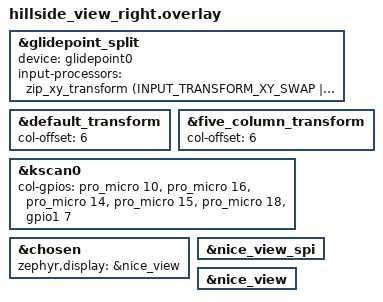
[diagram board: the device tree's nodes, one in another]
/*
 * Copyright (c) 2022 The ZMK Contributors
 *
 * SPDX-License-Identifier: MIT
 */

#include "hillside_view.dtsi"

#include <input/processors.dtsi>
#include <dt-bindings/zmk/input_transform.h>
#include <dt-bindings/input/input-event-codes.h>

&glidepoint_split {
    device = <&glidepoint0>;

    input-processors = <&zip_xy_transform (INPUT_TRANSFORM_XY_SWAP | INPUT_TRANSFORM_X_INVERT | INPUT_TRANSFORM_Y_INVERT)>;
};

&default_transform {
  col-offset = <6>;
};

&five_column_transform {
    col-offset = <6>;
};

&kscan0 {
  col-gpios
    = <&pro_micro 10 GPIO_ACTIVE_HIGH>
    , <&pro_micro 16 GPIO_ACTIVE_HIGH>
    , <&pro_micro 14 GPIO_ACTIVE_HIGH>
    , <&pro_micro 15 GPIO_ACTIVE_HIGH>
    , <&pro_micro 18 GPIO_ACTIVE_HIGH>
    , <&gpio1 7 GPIO_ACTIVE_HIGH>
    ;
};

&chosen {
  zephyr,display = &nice_view;
};

&nice_view_spi {
  status = "okay";
};

&nice_view {
  status = "okay";
};
